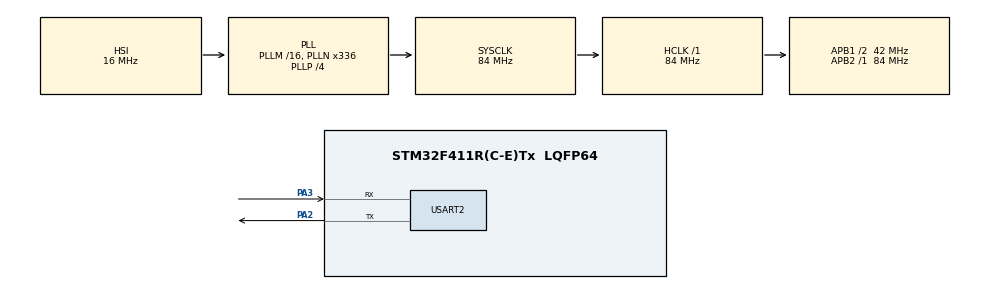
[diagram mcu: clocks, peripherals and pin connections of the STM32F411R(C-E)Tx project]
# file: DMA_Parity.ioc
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Dma.Request0=USART2_RX
Dma.Request1=USART2_TX
Dma.USART2_RX.0.Direction=DMA_PERIPH_TO_MEMORY
Dma.USART2_RX.0.FIFOMode=DMA_FIFOMODE_DISABLE
Dma.USART2_RX.0.Instance=DMA1_Stream5
Dma.USART2_RX.0.MemDataAlignment=DMA_MDATAALIGN_BYTE
Dma.USART2_RX.0.MemInc=DMA_MINC_ENABLE
Dma.USART2_RX.0.Mode=DMA_CIRCULAR
Dma.USART2_RX.0.PeriphDataAlignment=DMA_PDATAALIGN_BYTE
Dma.USART2_RX.0.PeriphInc=DMA_PINC_DISABLE
Dma.USART2_RX.0.Priority=DMA_PRIORITY_LOW
Dma.USART2_TX.1.Direction=DMA_MEMORY_TO_PERIPH
Dma.USART2_TX.1.FIFOMode=DMA_FIFOMODE_DISABLE
Dma.USART2_TX.1.Instance=DMA1_Stream6
Dma.USART2_TX.1.MemDataAlignment=DMA_MDATAALIGN_BYTE
Dma.USART2_TX.1.MemInc=DMA_MINC_ENABLE
Dma.USART2_TX.1.Mode=DMA_CIRCULAR
Dma.USART2_TX.1.PeriphDataAlignment=DMA_PDATAALIGN_BYTE
Dma.USART2_TX.1.PeriphInc=DMA_PINC_DISABLE
Dma.USART2_TX.1.Priority=DMA_PRIORITY_LOW
Mcu.Family=STM32F4
Mcu.Name=STM32F411R(C-E)Tx
Mcu.Package=LQFP64
NVIC.DMA1_Stream5_IRQn=true\:0\:0\:false\:false\:true\:false\:true\:true
NVIC.DMA1_Stream6_IRQn=true\:0\:0\:false\:false\:true\:false\:true\:true
NVIC.PriorityGroup=NVIC_PRIORITYGROUP_0
PA2.Mode=Asynchronous
PA2.Signal=USART2_TX
PA3.Mode=Asynchronous
PA3.Signal=USART2_RX
PC14-OSC32_IN.Mode=LSE-External-Oscillator
PC14-OSC32_IN.Signal=RCC_OSC32_IN
PC15-OSC32_OUT.Mode=LSE-External-Oscillator
PC15-OSC32_OUT.Signal=RCC_OSC32_OUT
ProjectManager.HeapSize=0x200
ProjectManager.StackSize=0x400
ProjectManager.TargetToolchain=STM32CubeIDE
RCC.48MHZClocksFreq_Value=84000000
RCC.AHBFreq_Value=84000000
RCC.APB1CLKDivider=RCC_HCLK_DIV2
RCC.APB1Freq_Value=42000000
RCC.APB1TimFreq_Value=84000000
RCC.APB2Freq_Value=84000000
RCC.APB2TimFreq_Value=84000000
RCC.CortexFreq_Value=84000000
RCC.FLatency-AdvancedSettings=FLASH_LATENCY_2
RCC.HCLKFreq_Value=84000000
RCC.HSE_VALUE=8000000
RCC.HSI_VALUE=16000000
RCC.PLLN=336
RCC.PLLP=RCC_PLLP_DIV4
RCC.SYSCLKFreq_VALUE=84000000
RCC.SYSCLKSource=RCC_SYSCLKSOURCE_PLLCLK
RCC.VCOOutputFreq_Value=336000000
USART2.Parity=PARITY_EVEN
USART2.VirtualMode=VM_ASYNC
USART2.WordLength=WORDLENGTH_8B
board=NUCLEO-F411RE

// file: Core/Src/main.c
/* USER CODE BEGIN Header */
/**
  ******************************************************************************
  * @file           : main.c
  * @brief          : Main program body
  ******************************************************************************
  * @attention
  *
  * Copyright (c) 2025 STMicroelectronics.
  * All rights reserved.
  *
  * This software is licensed under terms that can be found in the LICENSE file
  * in the root directory of this software component.
  * If no LICENSE file comes with this software, it is provided AS-IS.
  *
  ******************************************************************************
  */
/* USER CODE END Header */
#include "main.h"

UART_HandleTypeDef huart2;
DMA_HandleTypeDef hdma_usart2_rx;
DMA_HandleTypeDef hdma_usart2_tx;

void SystemClock_Config(void);
static void MX_GPIO_Init(void);
static void MX_DMA_Init(void);
static void MX_USART2_UART_Init(void);

int main(void)
{

  /* USER CODE BEGIN 1 */
	//uint8_t txData[25] = "Hello";
	uint8_t rxData[5]="Hello";

  /* USER CODE END 1 */

  /* MCU Configuration--------------------------------------------------------*/

  /* Reset of all peripherals, Initializes the Flash interface and the Systick. */
  HAL_Init();

  /* Configure the system clock */
  SystemClock_Config();

  /* Initialize all configured peripherals */
  MX_GPIO_Init();
  MX_DMA_Init();
  MX_USART2_UART_Init();

  /* Infinite loop */
  while (1)
  {

    /* USER CODE BEGIN 3 */
	  //HAL_UART_Receive(&huart2, (uint8_t *)&txData, sizeof(txData), 1000);
	  HAL_UART_Transmit_DMA(&huart2, (uint8_t *)&rxData, sizeof(rxData), 1000);
	  HAL_Delay(500);

  }
  /* USER CODE END 3 */
}

void SystemClock_Config(void)
{
  RCC_OscInitTypeDef RCC_OscInitStruct = {0};
  RCC_ClkInitTypeDef RCC_ClkInitStruct = {0};

  /** Configure the main internal regulator output voltage
  */
  __HAL_RCC_PWR_CLK_ENABLE();
  __HAL_PWR_VOLTAGESCALING_CONFIG(PWR_REGULATOR_VOLTAGE_SCALE1);

  /** Initializes the RCC Oscillators according to the specified parameters
  * in the RCC_OscInitTypeDef structure.
  */
  RCC_OscInitStruct.OscillatorType = RCC_OSCILLATORTYPE_HSI;
  RCC_OscInitStruct.HSIState = RCC_HSI_ON;
  RCC_OscInitStruct.HSICalibrationValue = RCC_HSICALIBRATION_DEFAULT;
  RCC_OscInitStruct.PLL.PLLState = RCC_PLL_ON;
  RCC_OscInitStruct.PLL.PLLSource = RCC_PLLSOURCE_HSI;
  RCC_OscInitStruct.PLL.PLLM = 16;
  RCC_OscInitStruct.PLL.PLLN = 336;
  RCC_OscInitStruct.PLL.PLLP = RCC_PLLP_DIV4;
  RCC_OscInitStruct.PLL.PLLQ = 4;
  if (HAL_RCC_OscConfig(&RCC_OscInitStruct) != HAL_OK)
  {
    Error_Handler();
  }

  /** Initializes the CPU, AHB and APB buses clocks
  */
  RCC_ClkInitStruct.ClockType = RCC_CLOCKTYPE_HCLK|RCC_CLOCKTYPE_SYSCLK
                              |RCC_CLOCKTYPE_PCLK1|RCC_CLOCKTYPE_PCLK2;
  RCC_ClkInitStruct.SYSCLKSource = RCC_SYSCLKSOURCE_PLLCLK;
  RCC_ClkInitStruct.AHBCLKDivider = RCC_SYSCLK_DIV1;
  RCC_ClkInitStruct.APB1CLKDivider = RCC_HCLK_DIV2;
  RCC_ClkInitStruct.APB2CLKDivider = RCC_HCLK_DIV1;

  if (HAL_RCC_ClockConfig(&RCC_ClkInitStruct, FLASH_LATENCY_2) != HAL_OK)
  {
    Error_Handler();
  }
}

static void MX_USART2_UART_Init(void)
{

  huart2.Instance = USART2;
  huart2.Init.BaudRate = 115200;
  huart2.Init.WordLength = UART_WORDLENGTH_8B;
  huart2.Init.StopBits = UART_STOPBITS_1;
  huart2.Init.Parity = UART_PARITY_EVEN;
  huart2.Init.Mode = UART_MODE_TX_RX;
  huart2.Init.HwFlowCtl = UART_HWCONTROL_NONE;
  huart2.Init.OverSampling = UART_OVERSAMPLING_16;
  if (HAL_UART_Init(&huart2) != HAL_OK)
  {
    Error_Handler();
  }

}

static void MX_DMA_Init(void)
{

  /* DMA controller clock enable */
  __HAL_RCC_DMA1_CLK_ENABLE();

  /* DMA interrupt init */
  /* DMA1_Stream5_IRQn interrupt configuration */
  HAL_NVIC_SetPriority(DMA1_Stream5_IRQn, 0, 0);
  HAL_NVIC_EnableIRQ(DMA1_Stream5_IRQn);
  /* DMA1_Stream6_IRQn interrupt configuration */
  HAL_NVIC_SetPriority(DMA1_Stream6_IRQn, 0, 0);
  HAL_NVIC_EnableIRQ(DMA1_Stream6_IRQn);

}

static void MX_GPIO_Init(void)
{

  /* GPIO Ports Clock Enable */
  __HAL_RCC_GPIOC_CLK_ENABLE();
  __HAL_RCC_GPIOA_CLK_ENABLE();

}

void Error_Handler(void)
{
  __disable_irq();
  while (1)
  {
  }
}
